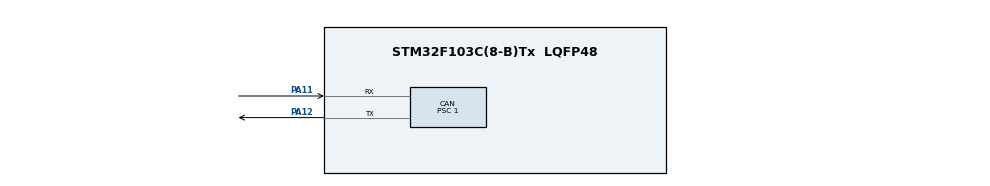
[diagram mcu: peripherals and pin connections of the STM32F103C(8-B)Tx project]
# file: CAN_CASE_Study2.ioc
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CAN.BS1=CAN_BS1_6TQ
CAN.CalculateBaudRate=1000000
CAN.CalculateTimeBit=1000
CAN.CalculateTimeQuantum=125.0
CAN.Prescaler=1
Mcu.Family=STM32F1
Mcu.Name=STM32F103C(8-B)Tx
Mcu.Package=LQFP48
NVIC.CAN1_SCE_IRQn=true\:0\:0\:false\:false\:true\:true\:true\:true
NVIC.PriorityGroup=NVIC_PRIORITYGROUP_4
NVIC.USB_HP_CAN1_TX_IRQn=true\:0\:0\:false\:false\:true\:true\:true\:true
NVIC.USB_LP_CAN1_RX0_IRQn=true\:0\:0\:false\:false\:true\:true\:true\:true
PA11.Mode=CAN_Activate
PA11.Signal=CAN_RX
PA12.Mode=CAN_Activate
PA12.Signal=CAN_TX
PA13.Mode=Serial_Wire
PA13.Signal=SYS_JTMS-SWDIO
PA14.Mode=Serial_Wire
PA14.Signal=SYS_JTCK-SWCLK
ProjectManager.HeapSize=0x200
ProjectManager.StackSize=0x400
ProjectManager.TargetToolchain=STM32CubeIDE
RCC.APB1Freq_Value=8000000
RCC.APB2Freq_Value=8000000
board=custom

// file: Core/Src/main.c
/* USER CODE BEGIN Header */
/**
  ******************************************************************************
  * @file           : main.c
  * @brief          : Main program body
  ******************************************************************************
  * @attention
  *
  * Copyright (c) 2024 STMicroelectronics.
  * All rights reserved.
  *
  * This software is licensed under terms that can be found in the LICENSE file
  * in the root directory of this software component.
  * If no LICENSE file comes with this software, it is provided AS-IS.
  *
  ******************************************************************************
  */
/* USER CODE END Header */
#include "main.h"

CAN_HandleTypeDef hcan;

void SystemClock_Config(void);
static void MX_GPIO_Init(void);
static void MX_CAN_Init(void);

/* USER CODE BEGIN 0 */

unsigned char TX_DATA[8];
uint8_t  FrameNo=0;
uint8_t RX_DATA[8];
uint16_t RXID,RXDLC=0;
uint8_t Speed;

void CAN_TX(uint32_t ID, uint8_t DLC, uint8_t *payload, uint8_t polling_EN){

	uint8_t pTxMailbox, no_free_txMailBox=0;
	CAN_TxHeaderTypeDef pHeader;

	pHeader.DLC=DLC;
	pHeader.IDE=CAN_ID_STD;
	pHeader.RTR=CAN_RTR_DATA;
	pHeader.StdId=ID;

	no_free_txMailBox = HAL_CAN_GetTxMailboxesFreeLevel(&hcan);
	/*get the number of the free mailboxes*/

	if(no_free_txMailBox){

		//request a transmission of a new message
		if(HAL_CAN_AddTxMessage(&hcan,&pHeader,payload,&pTxMailbox)  != HAL_OK){

			Error_Handler();
		}

		if(polling_EN){
			//wait until Tx mailboxes is transmitted
			while(HAL_CAN_IsTxMessagePending(&hcan, pTxMailbox) );
		}
	}
}

void CAN_RX_Filter_init(uint16_t STD_Filter_ID, uint16_t STD_Filter_MASK){

CAN_FilterTypeDef sFilterConfig;

sFilterConfig.FilterActivation=CAN_FILTER_ENABLE;
sFilterConfig.FilterBank=0;
sFilterConfig.FilterFIFOAssignment=CAN_FILTER_FIFO0;

sFilterConfig.FilterMaskIdLow=0x0000;
sFilterConfig.FilterMaskIdHigh=STD_Filter_MASK<<5;
sFilterConfig.FilterIdHigh=STD_Filter_ID<<5;
sFilterConfig.FilterIdLow=0x0000;

sFilterConfig.FilterMode=CAN_FILTERMODE_IDMASK;
sFilterConfig.FilterScale=CAN_FILTERSCALE_32BIT;

if(HAL_CAN_ConfigFilter(&hcan, &sFilterConfig) != HAL_OK)
	Error_Handler();

}

void CAN_RX(uint32_t* ID, uint16_t *DLC, uint16_t payload, uint8_t polling_EN){

	CAN_RxHeaderTypeDef pHeader;

	if(polling_EN){

	   while(HAL_CAN_GetRxFifoFillLevel(&hcan,CAN_FILTER_FIFO0)==0);
	}

	if(HAL_CAN_GetRxMessage(&hcan,CAN_FILTER_FIFO0,&pHeader,payload) != HAL_OK)
		Error_Handler();

	*ID=pHeader.StdId;
	*DLC=pHeader.DLC;

}

void HAL_CAN_TxMailbox0CompleteCallback(CAN_HandleTypeDef * hcan){

}

void HAL_CAN_RxFifo0MsgPendingCallback(CAN_HandleTypeDef * hcan){

	CAN_RX(&RXID,&RXDLC,RX_DATA,0);
	Speed=RX_DATA[0];
}

void HAL_CAN_ErrorCallback(CAN_HandleTypeDef * hcan){

	if((hcan->ErrorCode & HAL_CAN_ERROR_TX_TERR0) == HAL_CAN_ERROR_TX_TERR0){

	}
}

/* USER CODE END 0 */

int main(void)
{

  /* MCU Configuration--------------------------------------------------------*/

  /* Reset of all peripherals, Initializes the Flash interface and the Systick. */
  HAL_Init();

  /* Configure the system clock */
  SystemClock_Config();

  /* Initialize all configured peripherals */
  MX_GPIO_Init();
  MX_CAN_Init();
  /* USER CODE BEGIN 2 */

  /*1-RX Filter
   *2-Interrupt CAN notification
   *3-start CAN   */

  CAN_RX_Filter_init(0x3AB, 0x7FF);//rx filter

  if( HAL_CAN_ActivateNotification(&hcan, (CAN_IT_TX_MAILBOX_EMPTY|CAN_IT_RX_FIFO0_MSG_PENDING) ) != HAL_OK){

	  Error_Handler();
  }

  if(HAL_CAN_Start(&hcan) != HAL_OK){

	  Error_Handler();
  }

    /* USER CODE END 2 */
#define ACC 1
#define NoACC  0
  TX_DATA[0]=ACC;
  /* Infinite loop */
  while (1)
  {

	  HAL_Delay(1000);
	  CAN_TX(0x030, 1, TX_DATA, 0);
	  TX_DATA[0] ^=1;
  }
}

void SystemClock_Config(void)
{
  RCC_OscInitTypeDef RCC_OscInitStruct = {0};
  RCC_ClkInitTypeDef RCC_ClkInitStruct = {0};

  /** Initializes the RCC Oscillators according to the specified parameters
  * in the RCC_OscInitTypeDef structure.
  */
  RCC_OscInitStruct.OscillatorType = RCC_OSCILLATORTYPE_HSI;
  RCC_OscInitStruct.HSIState = RCC_HSI_ON;
  RCC_OscInitStruct.HSICalibrationValue = RCC_HSICALIBRATION_DEFAULT;
  RCC_OscInitStruct.PLL.PLLState = RCC_PLL_NONE;
  if (HAL_RCC_OscConfig(&RCC_OscInitStruct) != HAL_OK)
  {
    Error_Handler();
  }

  /** Initializes the CPU, AHB and APB buses clocks
  */
  RCC_ClkInitStruct.ClockType = RCC_CLOCKTYPE_HCLK|RCC_CLOCKTYPE_SYSCLK
                              |RCC_CLOCKTYPE_PCLK1|RCC_CLOCKTYPE_PCLK2;
  RCC_ClkInitStruct.SYSCLKSource = RCC_SYSCLKSOURCE_HSI;
  RCC_ClkInitStruct.AHBCLKDivider = RCC_SYSCLK_DIV1;
  RCC_ClkInitStruct.APB1CLKDivider = RCC_HCLK_DIV1;
  RCC_ClkInitStruct.APB2CLKDivider = RCC_HCLK_DIV1;

  if (HAL_RCC_ClockConfig(&RCC_ClkInitStruct, FLASH_LATENCY_0) != HAL_OK)
  {
    Error_Handler();
  }
}

static void MX_CAN_Init(void)
{

  hcan.Instance = CAN1;
  hcan.Init.Prescaler = 1;
  hcan.Init.Mode = CAN_MODE_NORMAL;
  hcan.Init.SyncJumpWidth = CAN_SJW_1TQ;
  hcan.Init.TimeSeg1 = CAN_BS1_6TQ;
  hcan.Init.TimeSeg2 = CAN_BS2_1TQ;
  hcan.Init.TimeTriggeredMode = DISABLE;
  hcan.Init.AutoBusOff = DISABLE;
  hcan.Init.AutoWakeUp = DISABLE;
  hcan.Init.AutoRetransmission = DISABLE;
  hcan.Init.ReceiveFifoLocked = DISABLE;
  hcan.Init.TransmitFifoPriority = DISABLE;
  if (HAL_CAN_Init(&hcan) != HAL_OK)
  {
    Error_Handler();
  }

}

static void MX_GPIO_Init(void)
{

  /* GPIO Ports Clock Enable */
  __HAL_RCC_GPIOA_CLK_ENABLE();

}

void Error_Handler(void)
{
  __disable_irq();
  while (1)
  {
  }
}
